# R7FA6M3AH register map
Vendor: Renesas; Series: RA6; File version: 1.2
CPU: CM4 r0p1, little endian, MPU, FPU, VTOR, 4 interrupt priority bits
Registers are 32-bit, read-write, reset 0x0 unless marked. A register's access mark holds for its fields unless they carry their own. Offsets are from the block's base; [hi:lo] are bit positions; {n}, {i} and the like mark numbered series; 'fields as' and 'values as' point back to an identical list.

## BUS — BUS Control
Base 0x40003000
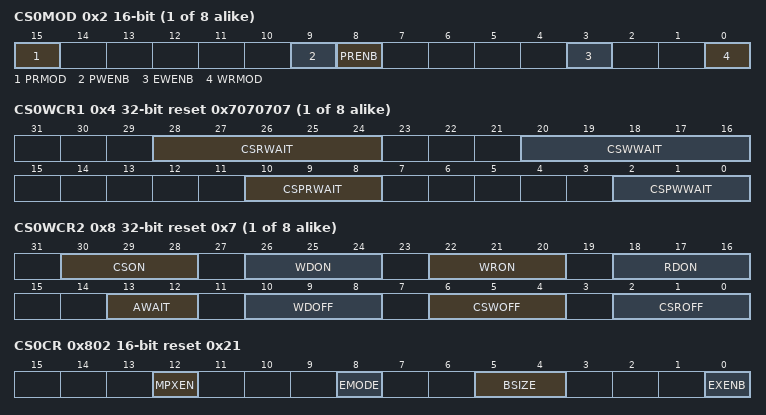
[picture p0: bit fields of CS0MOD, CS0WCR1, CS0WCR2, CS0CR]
{0x2+0x10*i} CS{i}MOD (i=0..7) 16-bit — CS{i} Mode Register
  [15] PRMOD — Page Read Access Mode Select
  [9] PWENB — Page Write Access Enable
  [8] PRENB — Page Read Access Enable
  [3] EWENB — External Wait Enable
  [0] WRMOD — Write Access Mode Select
{0x4+0x10*i} CS{i}WCR1 (i=0..7) reset 0x7070707 — CS{i} Wait Control Register 1
  [28:24] CSRWAIT — Normal Read Cycle Wait Select
  [20:16] CSWWAIT — Normal Write Cycle Wait Select
  [10:8] CSPRWAIT — Page Read Cycle Wait SelectNOTE: The CSPRWAIT value is valid only when the PRENB bit in CSnMOD is set to 1.
  [2:0] CSPWWAIT — Page Write Cycle Wait SelectNOTE: The CSPWWAIT value is valid only when the PWENB bit in CSnMOD is set to 1.
{0x8+0x10*i} CS{i}WCR2 (i=0..7) reset 0x7 — CS{i} Wait Control Register 2
  [30:28] CSON — CS Assert Wait Select
  [26:24] WDON — Write Data Output Wait Select
  [22:20] WRON — WR Assert Wait Select
  [18:16] RDON — RD Assert Wait Select
  [13:12] AWAIT — Address Cycle Wait Select
  [10:8] WDOFF — Write Data Output Extension Cycle Select
  [6:4] CSWOFF — Write,Access CS Extension Cycle Select
  [2:0] CSROFF — Read,Access CS Extension Cycle Select
0x802 CS0CR 16-bit reset 0x21 — CS0 Control Register
  [12] MPXEN — Address/Data Multiplexed I/O Interface Select
  [8] EMODE — Endian Mode
  [5:4] BSIZE — External Bus Width Select
  [0] EXENB — Operation Enable
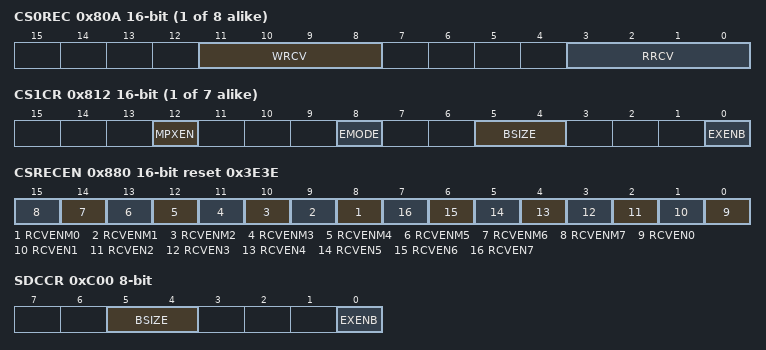
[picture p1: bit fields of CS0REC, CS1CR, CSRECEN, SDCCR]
{0x80A+0x10*i} CS{i}REC (i=0..7) 16-bit — CS{i} Recovery Cycle Register
  [11:8] WRCV — Write Recovery
  [3:0] RRCV — Read Recovery
{0x802+0x10*i} CS{i}CR (i=1..7) 16-bit — CS{i} Control Register
  fields as CS0CR
0x880 CSRECEN 16-bit reset 0x3E3E — CS Recovery Cycle Insertion Enable Register
  [n+8] RCVENM{n} (n=0..7) — Multiplexed Bus Recovery Cycle Insertion Enable {n}
  [n] RCVEN{n} (n=0..7) — Separate Bus Recovery Cycle Insertion Enable {n}
0xC00 SDCCR 8-bit — SDC Control Register
  [5:4] BSIZE — SDRAM Bus Width Select
  [0] EXENB — Operation Enable
0xC01 SDCMOD 8-bit — SDC Mode Register
  [0] EMODE — Endian Mode
0xC02 SDAMOD 8-bit — SDRAM Access Mode Register
  [0] BE — Continuous Access Enable
0xC10 SDSELF 8-bit — SDRAM Self,Refresh Control Register
  [0] SFEN — SDRAM Self,Refresh Enable
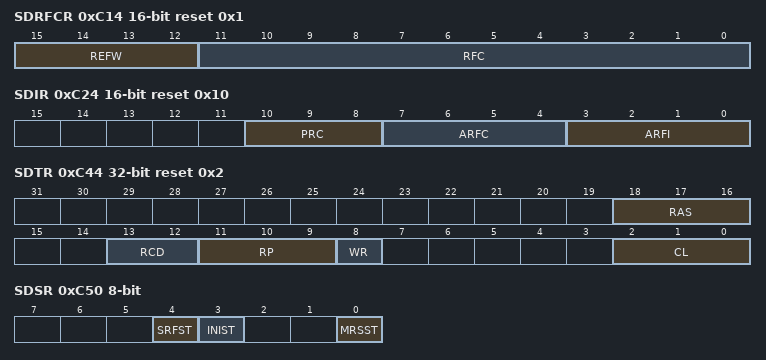
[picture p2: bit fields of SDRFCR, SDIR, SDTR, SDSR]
0xC14 SDRFCR 16-bit reset 0x1 — SDRAM Refresh Control Register
  [15:12] REFW — Auto,Refresh Cycle/ Self,Refresh Clearing Cycle Count Setting. ( REFW+1 Cycles )
  [11:0] RFC — Auto,Refresh Request Interval Setting
0xC16 SDRFEN 8-bit — SDRAM Auto,Refresh Control Register
  [0] RFEN — Auto,Refresh Operation Enable
0xC20 SDICR 8-bit — SDRAM Initialization Sequence Control Register
  [0] INIRQ — Initialization Sequence Start
0xC24 SDIR 16-bit reset 0x10 — SDRAM Initialization Register
  [10:8] PRC — Initialization Precharge Cycle Count (PRC+3 cycles)
  [7:4] ARFC — Initialization Auto,Refresh Count
  [3:0] ARFI — Initialization Auto,Refresh Interval (ARFI+3 cycles )
0xC40 SDADR 8-bit — SDRAM Address Register
  [1:0] MXC — Address Multiplex Select
0xC44 SDTR reset 0x2 — SDRAM Timing Register
  [18:16] RAS — Row Active Interval
  [13:12] RCD — Row Column Latency ( RCD+1 cycles )
  [11:9] RP — Row Precharge Interval ( RP+1 cycles )
  [8] WR — Write Recovery Interval
  [2:0] CL — SDRAMC Column Latency
0xC48 SDMOD 16-bit — SDRAM Mode Register
  [14:0] MR — Mode Register SettingWriting to these bits: Mode register set command is issued.
0xC50 SDSR 8-bit ro — SDRAM Status Register
  [4] SRFST — Self,Refresh Transition/Recovery Status
  [3] INIST — Initialization Status
  [0] MRSST — Mode Register Setting Status
0x1000 BUSMCNT{x} (x=M4I,M4D; step 0x4) 16-bit — Master Bus Control Register {x}
  [15] IERES — Ignore Error Responses
0x1008 BUSMCNTSYS 16-bit — Master Bus Control Register SYS
  [15] IERES — Ignore Error Responses
0x100C BUSMCNTDMA 16-bit — Master Bus Control Register DMA
  [15] IERES — Ignore Error Responses
0x1010 BUSMCNT{x}_1 (x=EDM,GPX; step 0x4) 16-bit — Master Bus Control Register {x}
  [15] IERES — Ignore Error Responses
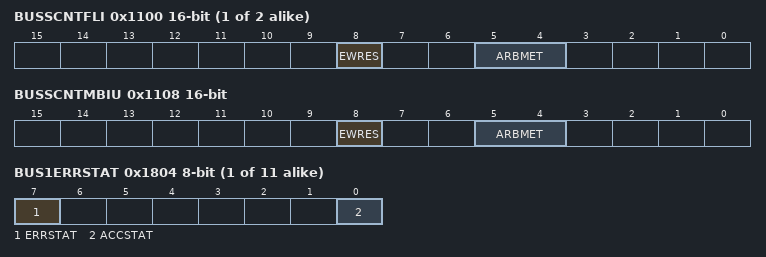
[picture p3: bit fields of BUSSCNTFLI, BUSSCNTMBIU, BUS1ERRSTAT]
0x1100 BUSSCNT{x} (x=FLI,RAMH; step 0x4) 16-bit — Slave Bus Control Register {x}
  [8] EWRES — Early Write ResponseWhether the next write request is accepted or not until a response for the write transaction comes back.
  [5:4] ARBMET — Arbitration MethodSpecify the priority between groups
0x1108 BUSSCNTMBIU 16-bit — Slave Bus Control Register MBIU
  fields as BUSSCNT{x}
0x110C BUSSCNT{x}_1 (x=RAM0,RAM1; step 0x4) 16-bit — Slave Bus Control Register {x}
  fields as BUSSCNT{x}
0x1114 BUSSCNT{x}_2 (x=P0B,P2B,P3B,P4B; step 0x4) 16-bit — Slave Bus Control Register {x}
  fields as BUSSCNT{x}
0x1128 BUSSCNT{x}_3 (x=P6B,P7B; step 0x4) 16-bit — Slave Bus Control Register {x}
  fields as BUSSCNT{x}
0x1130 BUSSCNT{x}_4 (x=FBU,EXT,EXT2,GPX; step 0x4) 16-bit — Slave Bus Control Register {x}
  fields as BUSSCNT{x}
{0x17F0+0x10*i} BUS{i}ERRADD (i=1..11) ro reset not defined — Bus Error Address Register {i}
  [31:0] BERAD — Bus Error AddressWhen a bus error occurs, It stores an error address.
{0x17F4+0x10*i} BUS{i}ERRSTAT (i=1..11) 8-bit ro (reset mask 0xFE) — Bus Error Status Register {i}
  [7] ERRSTAT — Bus Error StatusWhen bus error assert, error flag occurs.
  [0] ACCSTAT — Error access statusThe status at the time of the error
